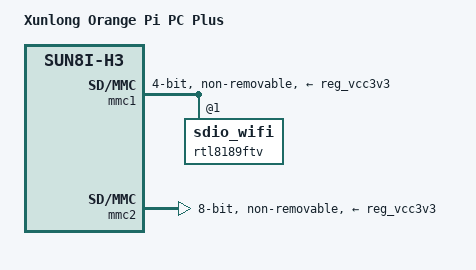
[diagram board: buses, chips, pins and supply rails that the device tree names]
/*
 * Copyright (C) 2016 Hans de Goede <hdegoede@redhat.com>
 *
 * This file is dual-licensed: you can use it either under the terms
 * of the GPL or the X11 license, at your option. Note that this dual
 * licensing only applies to this file, and not this project as a
 * whole.
 *
 *  a) This file is free software; you can redistribute it and/or
 *     modify it under the terms of the GNU General Public License as
 *     published by the Free Software Foundation; either version 2 of the
 *     License, or (at your option) any later version.
 *
 *     This file is distributed in the hope that it will be useful,
 *     but WITHOUT ANY WARRANTY; without even the implied warranty of
 *     MERCHANTABILITY or FITNESS FOR A PARTICULAR PURPOSE.  See the
 *     GNU General Public License for more details.
 *
 * Or, alternatively,
 *
 *  b) Permission is hereby granted, free of charge, to any person
 *     obtaining a copy of this software and associated documentation
 *     files (the "Software"), to deal in the Software without
 *     restriction, including without limitation the rights to use,
 *     copy, modify, merge, publish, distribute, sublicense, and/or
 *     sell copies of the Software, and to permit persons to whom the
 *     Software is furnished to do so, subject to the following
 *     conditions:
 *
 *     The above copyright notice and this permission notice shall be
 *     included in all copies or substantial portions of the Software.
 *
 *     THE SOFTWARE IS PROVIDED "AS IS", WITHOUT WARRANTY OF ANY KIND,
 *     EXPRESS OR IMPLIED, INCLUDING BUT NOT LIMITED TO THE WARRANTIES
 *     OF MERCHANTABILITY, FITNESS FOR A PARTICULAR PURPOSE AND
 *     NONINFRINGEMENT. IN NO EVENT SHALL THE AUTHORS OR COPYRIGHT
 *     HOLDERS BE LIABLE FOR ANY CLAIM, DAMAGES OR OTHER LIABILITY,
 *     WHETHER IN AN ACTION OF CONTRACT, TORT OR OTHERWISE, ARISING
 *     FROM, OUT OF OR IN CONNECTION WITH THE SOFTWARE OR THE USE OR
 *     OTHER DEALINGS IN THE SOFTWARE.
 */

/* The Orange Pi PC Plus is an extended version of the regular PC */
#include "sun8i-h3-orangepi-pc.dts"

/ {
	model = "Xunlong Orange Pi PC Plus";
	compatible = "xunlong,orangepi-pc-plus", "allwinner,sun8i-h3";

	aliases {
		/* ethernet0 is the H3 emac, defined in sun8i-h3.dtsi */
		ethernet1 = &rtl8189ftv;
	};
};

&mmc1 {
	pinctrl-names = "default";
	pinctrl-0 = <&mmc1_pins_a>;
	vmmc-supply = <&reg_vcc3v3>;
	bus-width = <4>;
	non-removable;
	status = "okay";

	/*
	 * Explicitly define the sdio device, so that we can add an ethernet
	 * alias for it (which e.g. makes u-boot set a mac-address).
	 */
	rtl8189ftv: sdio_wifi@1 {
		reg = <1>;
	};
};

&mmc2 {
	pinctrl-names = "default";
	pinctrl-0 = <&mmc2_8bit_pins>;
	vmmc-supply = <&reg_vcc3v3>;
	bus-width = <8>;
	non-removable;
	cap-mmc-hw-reset;
	status = "okay";
};

&mmc2_8bit_pins {
	/* Increase drive strength for DDR modes */
	drive-strength = <40>;
	/* eMMC is missing pull-ups */
	bias-pull-up;
};

&emac {
	/* LEDs changed to active high on the plus */
	/delete-property/ allwinner,leds-active-low;
};
